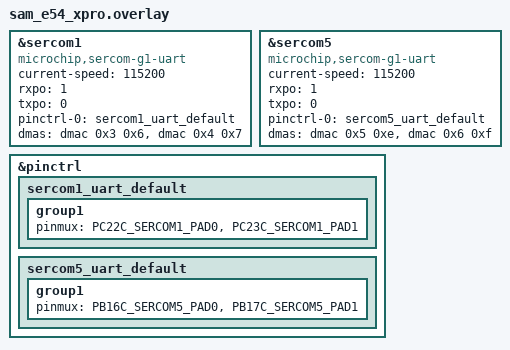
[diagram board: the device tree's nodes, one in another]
/*
 * Copyright (c) 2025 Microchip Technology Inc.
 *
 * SPDX-License-Identifier: Apache-2.0
 */

/*connect PB16 to PC23 and PB17 to PC22*/

dut: &sercom1 {
	compatible = "microchip,sercom-g1-uart";
	current-speed = <115200>;
	rxpo = <1>;
	txpo = <0>;
	#address-cells = <1>;
	#size-cells = <0>;
	status = "okay";

	pinctrl-0 = <&sercom1_uart_default>;
	pinctrl-names = "default";

	dmas = <&dmac 0x3 0x6>, <&dmac 0x4 0x7>;
	dma-names = "rx", "tx";
};

dut_aux: &sercom5 {
	compatible = "microchip,sercom-g1-uart";
	current-speed = <115200>;
	rxpo = <1>;
	txpo = <0>;
	#address-cells = <1>;
	#size-cells = <0>;
	status = "okay";

	pinctrl-0 = <&sercom5_uart_default>;
	pinctrl-names = "default";

	dmas = <&dmac 0x5 0xe>, <&dmac 0x6 0xf>;
	dma-names = "rx", "tx";
};

&pinctrl {
	sercom1_uart_default: sercom1_uart_default {
		group1 {
			pinmux = <PC22C_SERCOM1_PAD0>,
				 <PC23C_SERCOM1_PAD1>;
		};
	};

	sercom5_uart_default: sercom5_uart_default {
		group1 {
			pinmux = <PB16C_SERCOM5_PAD0>,
				 <PB17C_SERCOM5_PAD1>;
		};
	};
};
